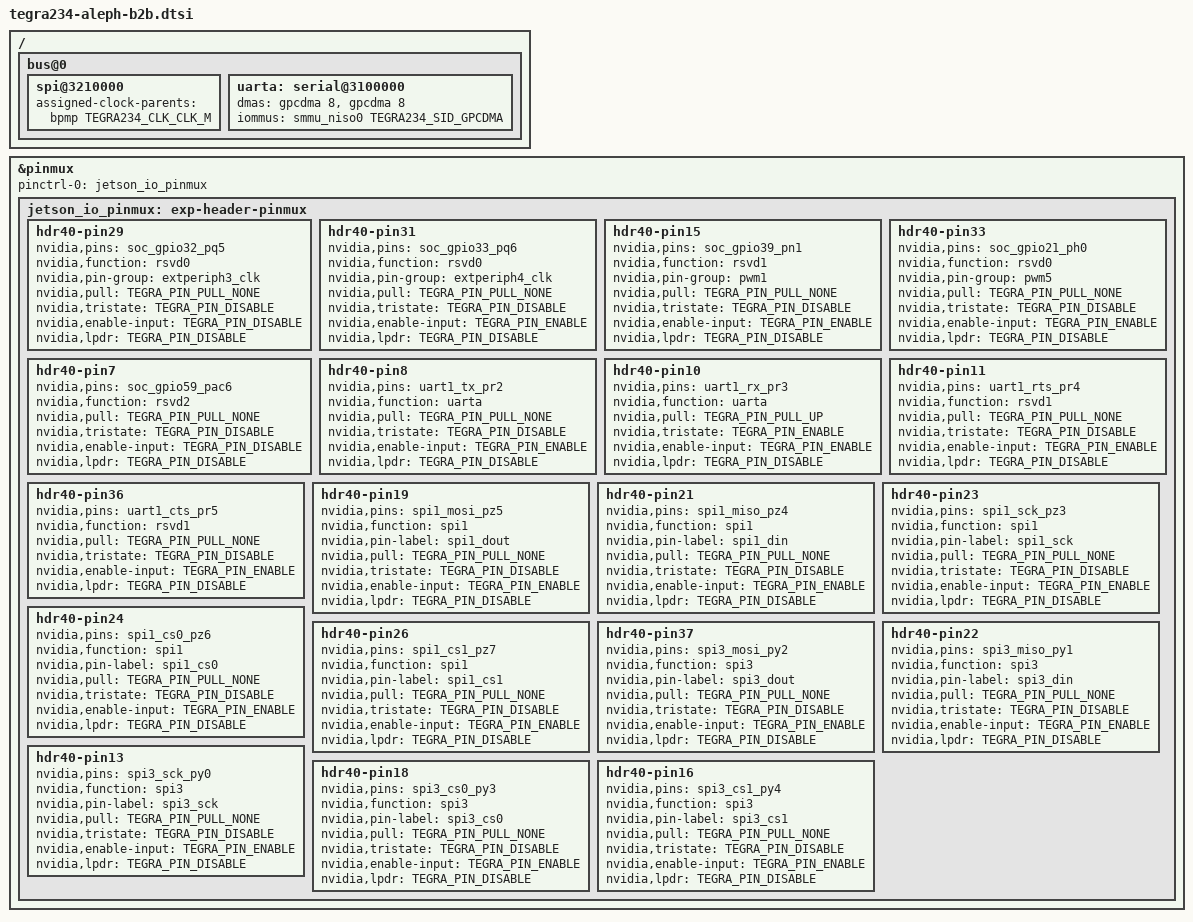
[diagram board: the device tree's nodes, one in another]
// SPDX-License-Identifier: GPL-2.0-only
// SPDX-FileCopyrightText: Copyright (c) 2021-2023, NVIDIA CORPORATION & AFFILIATES.  All rights reserved.
/*
 * Copyright (c) 2021-2023, NVIDIA CORPORATION & AFFILIATES.  All rights reserved.
 *
 * This program is free software; you can redistribute it and/or modify it
 * under the terms and conditions of the GNU General Public License,
 * version 2, as published by the Free Software Foundation.
 *
 * This program is distributed in the hope it will be useful, but WITHOUT
 * ANY WARRANTY; without even the implied warranty of MERCHANTABILITY or
 * FITNESS FOR A PARTICULAR PURPOSE.  See the GNU General Public License for
 * more details.
 *
 * You should have received a copy of the GNU General Public License
 * along with this program.  If not, see <http://www.gnu.org/licenses/>.
 */
#include <dt-bindings/pinctrl/pinctrl-tegra.h>
#include <dt-bindings/clock/tegra234-clock.h>

/ {
	bus@0 {
		spi@3210000{ /* SPI1 in B2B */
			/* For STM communication */
			assigned-clock-parents = <&bpmp TEGRA234_CLK_CLK_M>;
		};

		uarta: serial@3100000 { /* UART A */
			dmas = <&gpcdma 8>, <&gpcdma 8>;
			dma-names = "rx", "tx";
			iommus = <&smmu_niso0 TEGRA234_SID_GPCDMA>;
		};
	};
};

&pinmux {
	pinctrl-names = "default";
	pinctrl-0 = <&jetson_io_pinmux>;

	jetson_io_pinmux: exp-header-pinmux {

		// ********** GPIO **********

		// Jetson GPIO O (Aleph J5 GPIO Output Enable - TXU0304RUTR)
		// appears as soc_gpio32_pq5 in nvidia config template xlsm
		hdr40-pin29 {
			nvidia,pins = "soc_gpio32_pq5";
			nvidia,function = "rsvd0";
			nvidia,pin-group = "extperiph3_clk";
			nvidia,pull = <TEGRA_PIN_PULL_NONE>;
			nvidia,tristate = <TEGRA_PIN_DISABLE>;
			nvidia,enable-input = <TEGRA_PIN_DISABLE>;
			nvidia,lpdr = <TEGRA_PIN_DISABLE>;
		};

		// Jetson GPIO 11 (Aleph J5 GPIO 1)
		// appears as soc_gpio33_pq6 in nvidia config template xlsm
		hdr40-pin31 {
			nvidia,pins = "soc_gpio33_pq6";
			nvidia,function = "rsvd0";
			nvidia,pin-group = "extperiph4_clk";
			nvidia,pull = <TEGRA_PIN_PULL_NONE>;
			nvidia,tristate = <TEGRA_PIN_DISABLE>;
			nvidia,enable-input = <TEGRA_PIN_ENABLE>;
			nvidia,lpdr = <TEGRA_PIN_DISABLE>;
		};

		// Jetson GPIO 12 (Aleph J5 GPIO 2)
		// appears as soc_gpio39_pn1 in nvidia config template xlsm
		hdr40-pin15 {
			nvidia,pins = "soc_gpio39_pn1";
			nvidia,function = "rsvd1";
			nvidia,pin-group = "pwm1";
			nvidia,pull = <TEGRA_PIN_PULL_NONE>;
			nvidia,tristate = <TEGRA_PIN_DISABLE>;
			nvidia,enable-input = <TEGRA_PIN_ENABLE>;
			nvidia,lpdr = <TEGRA_PIN_DISABLE>;
		};

		// Jetson GPIO 13 (Aleph J5 GPIO 3)
		// appears as soc_gpio21_pq0 in nvidia config template xlsm
		hdr40-pin33 {
			nvidia,pins = "soc_gpio21_ph0";
			nvidia,function = "rsvd0";
			nvidia,pin-group = "pwm5";
			nvidia,pull = <TEGRA_PIN_PULL_NONE>;
			nvidia,tristate = <TEGRA_PIN_DISABLE>;
			nvidia,enable-input = <TEGRA_PIN_ENABLE>;
			nvidia,lpdr = <TEGRA_PIN_DISABLE>;
		};

		// Jetson GPIO 9 (Aleph STM BOOT0)
		// appears as soc_gpio59_pac6 in nvidia config template xlsm
		hdr40-pin7 {
			nvidia,pins = "soc_gpio59_pac6";
			nvidia,function = "rsvd2";
			nvidia,pull = <TEGRA_PIN_PULL_NONE>;
			nvidia,tristate = <TEGRA_PIN_DISABLE>;
			nvidia,enable-input = <TEGRA_PIN_DISABLE>;
			nvidia,lpdr = <TEGRA_PIN_DISABLE>;
		};

		// ********** UART **********

		// Jetson UART1 TX (Routed to STM)
		// appears as uart1_tx_pr2 in nvidia config template xlsm
		hdr40-pin8 {
			nvidia,pins = "uart1_tx_pr2";
			nvidia,function = "uarta";
			nvidia,pull = <TEGRA_PIN_PULL_NONE>;
			nvidia,tristate = <TEGRA_PIN_DISABLE>;
			nvidia,enable-input = <TEGRA_PIN_ENABLE>;
			nvidia,lpdr = <TEGRA_PIN_DISABLE>;
		};

		// Jetson UART1 RX (Routed to STM)
		// appears as uart1_rx_pr3 in nvidia config template xlsm
		hdr40-pin10 {
			nvidia,pins = "uart1_rx_pr3";
			nvidia,function = "uarta";
			nvidia,pull = <TEGRA_PIN_PULL_UP>;
			nvidia,tristate = <TEGRA_PIN_ENABLE>;
			nvidia,enable-input = <TEGRA_PIN_ENABLE>;
			nvidia,lpdr = <TEGRA_PIN_DISABLE>;
		};

		// Jetson UART1 RTS (not routed from Orin SODIMM)
		// appears as uart1_rts_pr4 in nvidia config template xlsm
		hdr40-pin11 {
			nvidia,pins = "uart1_rts_pr4";
			nvidia,function = "rsvd1";
			nvidia,pull = <TEGRA_PIN_PULL_NONE>;
			nvidia,tristate = <TEGRA_PIN_DISABLE>;
			nvidia,enable-input = <TEGRA_PIN_ENABLE>;
			nvidia,lpdr = <TEGRA_PIN_DISABLE>;
		};

		// Jetson UART1 CTS (not routed from Orin SODIMM)
		// appears as uart1_cts_pr5 in nvidia config template xlsm
		hdr40-pin36 {
			nvidia,pins = "uart1_cts_pr5";
			nvidia,function = "rsvd1";
			nvidia,pull = <TEGRA_PIN_PULL_NONE>;
			nvidia,tristate = <TEGRA_PIN_DISABLE>;
			nvidia,enable-input = <TEGRA_PIN_ENABLE>;
			nvidia,lpdr = <TEGRA_PIN_DISABLE>;
		};

		// ********** SPI **********

		// J1 - SPI 1 - STM
		hdr40-pin19 {
			nvidia,pins = "spi1_mosi_pz5";
			nvidia,function = "spi1";
			nvidia,pin-label = "spi1_dout";
			nvidia,pull = <TEGRA_PIN_PULL_NONE>;
			nvidia,tristate = <TEGRA_PIN_DISABLE>;
			nvidia,enable-input = <TEGRA_PIN_ENABLE>;
			nvidia,lpdr = <TEGRA_PIN_DISABLE>;
		};

		hdr40-pin21 {
			nvidia,pins = "spi1_miso_pz4";
			nvidia,function = "spi1";
			nvidia,pin-label = "spi1_din";
			nvidia,pull = <TEGRA_PIN_PULL_NONE>;
			nvidia,tristate = <TEGRA_PIN_DISABLE>;
			nvidia,enable-input = <TEGRA_PIN_ENABLE>;
			nvidia,lpdr = <TEGRA_PIN_DISABLE>;
		};

		hdr40-pin23 {
			nvidia,pins = "spi1_sck_pz3";
			nvidia,function = "spi1";
			nvidia,pin-label = "spi1_sck";
			nvidia,pull = <TEGRA_PIN_PULL_NONE>;
			nvidia,tristate = <TEGRA_PIN_DISABLE>;
			nvidia,enable-input = <TEGRA_PIN_ENABLE>;
			nvidia,lpdr = <TEGRA_PIN_DISABLE>;
		};

		hdr40-pin24 {
			nvidia,pins = "spi1_cs0_pz6";
			nvidia,function = "spi1";
			nvidia,pin-label = "spi1_cs0";
			nvidia,pull = <TEGRA_PIN_PULL_NONE>;
			nvidia,tristate = <TEGRA_PIN_DISABLE>;
			nvidia,enable-input = <TEGRA_PIN_ENABLE>;
			nvidia,lpdr = <TEGRA_PIN_DISABLE>;
		};

		hdr40-pin26 {
			nvidia,pins = "spi1_cs1_pz7";
			nvidia,function = "spi1";
			nvidia,pin-label = "spi1_cs1";
			nvidia,pull = <TEGRA_PIN_PULL_NONE>;
			nvidia,tristate = <TEGRA_PIN_DISABLE>;
			nvidia,enable-input = <TEGRA_PIN_ENABLE>;
			nvidia,lpdr = <TEGRA_PIN_DISABLE>;
		};

		hdr40-pin37 {
			nvidia,pins = "spi3_mosi_py2";
			nvidia,function = "spi3";
			nvidia,pin-label = "spi3_dout";
			nvidia,pull = <TEGRA_PIN_PULL_NONE>;
			nvidia,tristate = <TEGRA_PIN_DISABLE>;
			nvidia,enable-input = <TEGRA_PIN_ENABLE>;
			nvidia,lpdr = <TEGRA_PIN_DISABLE>;
		};

		hdr40-pin22 {
			nvidia,pins = "spi3_miso_py1";
			nvidia,function = "spi3";
			nvidia,pin-label = "spi3_din";
			nvidia,pull = <TEGRA_PIN_PULL_NONE>;
			nvidia,tristate = <TEGRA_PIN_DISABLE>;
			nvidia,enable-input = <TEGRA_PIN_ENABLE>;
			nvidia,lpdr = <TEGRA_PIN_DISABLE>;
		};

		hdr40-pin13 {
			nvidia,pins = "spi3_sck_py0";
			nvidia,function = "spi3";
			nvidia,pin-label = "spi3_sck";
			nvidia,pull = <TEGRA_PIN_PULL_NONE>;
			nvidia,tristate = <TEGRA_PIN_DISABLE>;
			nvidia,enable-input = <TEGRA_PIN_ENABLE>;
			nvidia,lpdr = <TEGRA_PIN_DISABLE>;
		};

		hdr40-pin18 {
			nvidia,pins = "spi3_cs0_py3";
			nvidia,function = "spi3";
			nvidia,pin-label = "spi3_cs0";
			nvidia,pull = <TEGRA_PIN_PULL_NONE>;
			nvidia,tristate = <TEGRA_PIN_DISABLE>;
			nvidia,enable-input = <TEGRA_PIN_ENABLE>;
			nvidia,lpdr = <TEGRA_PIN_DISABLE>;
		};

		hdr40-pin16 {
			nvidia,pins = "spi3_cs1_py4";
			nvidia,function = "spi3";
			nvidia,pin-label = "spi3_cs1";
			nvidia,pull = <TEGRA_PIN_PULL_NONE>;
			nvidia,tristate = <TEGRA_PIN_DISABLE>;
			nvidia,enable-input = <TEGRA_PIN_ENABLE>;
			nvidia,lpdr = <TEGRA_PIN_DISABLE>;
		};
	};
};
